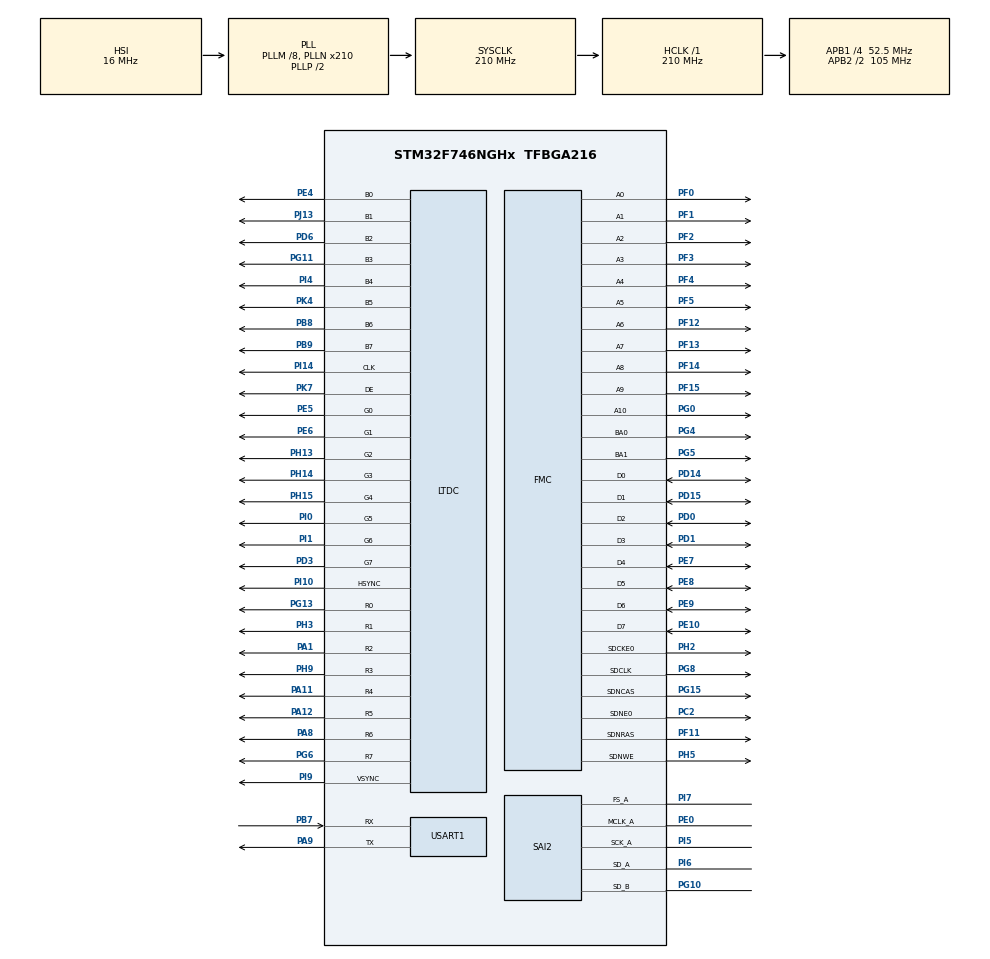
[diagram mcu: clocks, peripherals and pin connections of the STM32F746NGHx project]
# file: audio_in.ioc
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Dma.Request0=SAI2_B
Dma.SAI2_B.0.Direction=DMA_PERIPH_TO_MEMORY
Dma.SAI2_B.0.FIFOMode=DMA_FIFOMODE_DISABLE
Dma.SAI2_B.0.Instance=DMA2_Stream6
Dma.SAI2_B.0.MemDataAlignment=DMA_MDATAALIGN_WORD
Dma.SAI2_B.0.MemInc=DMA_MINC_ENABLE
Dma.SAI2_B.0.Mode=DMA_NORMAL
Dma.SAI2_B.0.PeriphDataAlignment=DMA_PDATAALIGN_WORD
Dma.SAI2_B.0.PeriphInc=DMA_PINC_DISABLE
Dma.SAI2_B.0.Priority=DMA_PRIORITY_LOW
Mcu.Family=STM32F7
Mcu.Name=STM32F746NGHx
Mcu.Package=TFBGA216
NVIC.DMA2_Stream6_IRQn=true\:0\:0\:false\:false\:true\:false\:true\:true
NVIC.PriorityGroup=NVIC_PRIORITYGROUP_4
NVIC.TIM1_UP_TIM10_IRQn=true\:15\:0\:false\:false\:true\:false\:true\:true
NVIC.TimeBase=TIM1_UP_TIM10_IRQn
NVIC.TimeBaseIP=TIM1
PA1.Mode=RGB888
PA1.Signal=LTDC_R2
PA11.Mode=RGB888
PA11.Signal=LTDC_R4
PA12.Mode=RGB888
PA12.Signal=LTDC_R5
PA8.Mode=RGB888
PA8.Signal=LTDC_R6
PA9.Mode=Asynchronous
PA9.Signal=USART1_TX
PB7.Mode=Asynchronous
PB7.Signal=USART1_RX
PB8.Mode=RGB888
PB8.Signal=LTDC_B6
PB9.Mode=RGB888
PB9.Signal=LTDC_B7
PC2.Mode=SdramChipSelect1_1
PC2.Signal=FMC_SDNE0
PD0.Signal=FMC_D2_DA2
PD1.Signal=FMC_D3_DA3
PD14.Signal=FMC_D0_DA0
PD15.Signal=FMC_D1_DA1
PD3.Mode=RGB888
PD3.Signal=LTDC_G7
PD6.Mode=RGB888
PD6.Signal=LTDC_B2
PE0.Mode=SAI_A_MasterWithClock
PE0.Signal=SAI2_MCLK_A
PE10.Signal=FMC_D7_DA7
PE4.Mode=RGB888
PE4.Signal=LTDC_B0
PE5.Mode=RGB888
PE5.Signal=LTDC_G0
PE6.Mode=RGB888
PE6.Signal=LTDC_G1
PE7.Signal=FMC_D4_DA4
PE8.Signal=FMC_D5_DA5
PE9.Signal=FMC_D6_DA6
PF0.Signal=FMC_A0
PF1.Signal=FMC_A1
PF11.Signal=FMC_SDNRAS
PF12.Signal=FMC_A6
PF13.Signal=FMC_A7
PF14.Signal=FMC_A8
PF15.Signal=FMC_A9
PF2.Signal=FMC_A2
PF3.Signal=FMC_A3
PF4.Signal=FMC_A4
PF5.Signal=FMC_A5
PG0.Signal=FMC_A10
PG10.Mode=SAI_B_SyncSlave
PG10.Signal=SAI2_SD_B
PG11.Mode=RGB888
PG11.Signal=LTDC_B3
PG13.Mode=RGB888
PG13.Signal=LTDC_R0
PG15.Signal=FMC_SDNCAS
PG4.Signal=FMC_A14_BA0
PG5.Signal=FMC_A15_BA1
PG6.Mode=RGB888
PG6.Signal=LTDC_R7
PG8.Signal=FMC_SDCLK
PH13.Mode=RGB888
PH13.Signal=LTDC_G2
PH14.Mode=RGB888
PH14.Signal=LTDC_G3
PH15.Mode=RGB888
PH15.Signal=LTDC_G4
PH2.Mode=SdramChipSelect1_1
PH2.Signal=FMC_SDCKE0
PH3.Mode=RGB888
PH3.Signal=LTDC_R1
PH5.Signal=FMC_SDNWE
PH9.Mode=RGB888
PH9.Signal=LTDC_R3
PI0.Mode=RGB888
PI0.Signal=LTDC_G5
PI1.Mode=RGB888
PI1.Signal=LTDC_G6
PI10.Mode=RGB888
PI10.Signal=LTDC_HSYNC
PI14.Mode=RGB888
PI14.Signal=LTDC_CLK
PI4.Mode=RGB888
PI4.Signal=LTDC_B4
PI5.Mode=SAI_A_MasterWithClock
PI5.Signal=SAI2_SCK_A
PI6.Mode=SAI_A_MasterWithClock
PI6.Signal=SAI2_SD_A
PI7.Mode=SAI_A_MasterWithClock
PI7.Signal=SAI2_FS_A
PI9.Mode=RGB888
PI9.Signal=LTDC_VSYNC
PJ13.Mode=RGB888
PJ13.Signal=LTDC_B1
PK4.Mode=RGB888
PK4.Signal=LTDC_B5
PK7.Mode=RGB888
PK7.Signal=LTDC_DE
ProjectManager.HeapSize=0x200
ProjectManager.StackSize=0x400
ProjectManager.TargetToolchain=STM32CubeIDE
RCC.AHBFreq_Value=210000000
RCC.APB1CLKDivider=RCC_HCLK_DIV4
RCC.APB1Freq_Value=52500000
RCC.APB1TimFreq_Value=105000000
RCC.APB2CLKDivider=RCC_HCLK_DIV2
RCC.APB2Freq_Value=105000000
RCC.APB2TimFreq_Value=210000000
RCC.CortexFreq_Value=210000000
RCC.HCLKFreq_Value=210000000
RCC.HSE_VALUE=25000000
RCC.HSI_VALUE=16000000
RCC.LSE_VALUE=32768
RCC.PLLM=8
RCC.PLLN=210
RCC.PLLSAIN=50
RCC.PLLSourceVirtual=RCC_PLLSOURCE_HSI
RCC.SYSCLKFreq_VALUE=210000000
RCC.SYSCLKSource=RCC_SYSCLKSOURCE_PLLCLK
RCC.USBFreq_Value=210000000
RCC.VCOOutputFreq_Value=420000000
SAI2.AudioFrequency-SAI_A_MasterWithClock=SAI_AUDIO_FREQUENCY_48K
SAI2.ErrorAudioFreq-SAI_A_MasterWithClock=1.72 %
SAI2.Instance-SAI_A_MasterWithClock=SAI$Index_Block_A
SAI2.Instance-SAI_B_SyncSlave=SAI$Index_Block_B
SAI2.MClockEnable-SAI_A_MasterWithClock=SAI_MASTERCLOCK_ENABLE
SAI2.RealAudioFreq-SAI_A_MasterWithClock=48.828 KHz
SAI2.VirtualMode-SAI_A_MasterWithClock=VM_MASTER
SAI2.VirtualMode-SAI_B_SyncSlave=VM_SLAVE
SH.FMC_A0.0=FMC_A0,11b-sda1
SH.FMC_A1.0=FMC_A1,11b-sda1
SH.FMC_A10.0=FMC_A10,11b-sda1
SH.FMC_A14_BA0.0=FMC_BA0,FourSdramBanks1
SH.FMC_A15_BA1.0=FMC_BA1,FourSdramBanks1
SH.FMC_A2.0=FMC_A2,11b-sda1
SH.FMC_A3.0=FMC_A3,11b-sda1
SH.FMC_A4.0=FMC_A4,11b-sda1
SH.FMC_A5.0=FMC_A5,11b-sda1
SH.FMC_A6.0=FMC_A6,11b-sda1
SH.FMC_A7.0=FMC_A7,11b-sda1
SH.FMC_A8.0=FMC_A8,11b-sda1
SH.FMC_A9.0=FMC_A9,11b-sda1
SH.FMC_D0_DA0.0=FMC_D0,sd-8b-d1
SH.FMC_D1_DA1.0=FMC_D1,sd-8b-d1
SH.FMC_D2_DA2.0=FMC_D2,sd-8b-d1
SH.FMC_D3_DA3.0=FMC_D3,sd-8b-d1
SH.FMC_D4_DA4.0=FMC_D4,sd-8b-d1
SH.FMC_D5_DA5.0=FMC_D5,sd-8b-d1
SH.FMC_D6_DA6.0=FMC_D6,sd-8b-d1
SH.FMC_D7_DA7.0=FMC_D7,sd-8b-d1
SH.FMC_SDCLK.0=FMC_SDCLK,11b-sda1
SH.FMC_SDNCAS.0=FMC_SDNCAS,11b-sda1
SH.FMC_SDNRAS.0=FMC_SDNRAS,11b-sda1
SH.FMC_SDNWE.0=FMC_SDNWE,11b-sda1
STMicroelectronics.X-CUBE-TOUCHGFX.4.23.0_IsPackSelfContextualization=true
USART1.VirtualMode-Asynchronous=VM_ASYNC
VP_DMA2D_VS_DMA2D.Mode=DMA2D_Activate
VP_SYS_VS_tim1.Mode=TIM1
board=STM32F746G-DISCO

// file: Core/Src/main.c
/* USER CODE BEGIN Header */
/**
  ******************************************************************************
  * @file           : main.c
  * @brief          : Main program body
  ******************************************************************************
  * @attention
  *
  * Copyright (c) 2024 STMicroelectronics.
  * All rights reserved.
  *
  * This software is licensed under terms that can be found in the LICENSE file
  * in the root directory of this software component.
  * If no LICENSE file comes with this software, it is provided AS-IS.
  *
  ******************************************************************************
  */
/* USER CODE END Header */
#include "main.h"

/* USER CODE BEGIN Includes */
#include "../Drivers/BSP/STM32746G-Discovery/stm32746g_discovery_audio.h"

/* USER CODE END Includes */

/* USER CODE BEGIN PD */
#define BUFF_SIZE 960
/* USER CODE END PD */

DMA2D_HandleTypeDef hdma2d;

LTDC_HandleTypeDef hltdc;

SAI_HandleTypeDef hsai_BlockA2;
SAI_HandleTypeDef hsai_BlockB2;
DMA_HandleTypeDef hdma_sai2_b;

UART_HandleTypeDef huart1;

SDRAM_HandleTypeDef hsdram1;

void SystemClock_Config(void);
void PeriphCommonClock_Config(void);
static void MX_GPIO_Init(void);
static void MX_DMA_Init(void);
static void MX_FMC_Init(void);
static void MX_USART1_UART_Init(void);
static void MX_DMA2D_Init(void);
static void MX_SAI2_Init(void);
static void MX_LTDC_Init(void);

int main(void)
{

  /* MCU Configuration--------------------------------------------------------*/

  /* Reset of all peripherals, Initializes the Flash interface and the Systick. */
  HAL_Init();

  /* Configure the system clock */
  SystemClock_Config();

/* Configure the peripherals common clocks */
  PeriphCommonClock_Config();

  /* Initialize all configured peripherals */
  MX_GPIO_Init();
  MX_DMA_Init();
  MX_FMC_Init();
  MX_USART1_UART_Init();
  MX_DMA2D_Init();
  MX_SAI2_Init();
  MX_LTDC_Init();
  /* USER CODE BEGIN 2 */
  BSP_AUDIO_IN_OUT_Init(INPUT_DEVICE_DIGITAL_MICROPHONE_2, OUTPUT_DEVICE_AUTO, AUDIO_FREQUENCY_48K, 0 ,0);
  uint16_t buf[BUFF_SIZE];
  BSP_AUDIO_IN_Record(buf, BUFF_SIZE);
  //BSP_AUDIO_OUT_Play(buf, BUFF_SIZE*2);
  /* USER CODE END 2 */

  /* Infinite loop */
  while (1)
  {

  }
}

void SystemClock_Config(void)
{
  RCC_OscInitTypeDef RCC_OscInitStruct = {0};
  RCC_ClkInitTypeDef RCC_ClkInitStruct = {0};

  /** Configure the main internal regulator output voltage
  */
  __HAL_RCC_PWR_CLK_ENABLE();
  __HAL_PWR_VOLTAGESCALING_CONFIG(PWR_REGULATOR_VOLTAGE_SCALE1);

  /** Initializes the RCC Oscillators according to the specified parameters
  * in the RCC_OscInitTypeDef structure.
  */
  RCC_OscInitStruct.OscillatorType = RCC_OSCILLATORTYPE_HSI;
  RCC_OscInitStruct.HSIState = RCC_HSI_ON;
  RCC_OscInitStruct.HSICalibrationValue = RCC_HSICALIBRATION_DEFAULT;
  RCC_OscInitStruct.PLL.PLLState = RCC_PLL_ON;
  RCC_OscInitStruct.PLL.PLLSource = RCC_PLLSOURCE_HSI;
  RCC_OscInitStruct.PLL.PLLM = 8;
  RCC_OscInitStruct.PLL.PLLN = 210;
  RCC_OscInitStruct.PLL.PLLP = RCC_PLLP_DIV2;
  RCC_OscInitStruct.PLL.PLLQ = 2;
  if (HAL_RCC_OscConfig(&RCC_OscInitStruct) != HAL_OK)
  {
    Error_Handler();
  }

  /** Activate the Over-Drive mode
  */
  if (HAL_PWREx_EnableOverDrive() != HAL_OK)
  {
    Error_Handler();
  }

  /** Initializes the CPU, AHB and APB buses clocks
  */
  RCC_ClkInitStruct.ClockType = RCC_CLOCKTYPE_HCLK|RCC_CLOCKTYPE_SYSCLK
                              |RCC_CLOCKTYPE_PCLK1|RCC_CLOCKTYPE_PCLK2;
  RCC_ClkInitStruct.SYSCLKSource = RCC_SYSCLKSOURCE_PLLCLK;
  RCC_ClkInitStruct.AHBCLKDivider = RCC_SYSCLK_DIV1;
  RCC_ClkInitStruct.APB1CLKDivider = RCC_HCLK_DIV4;
  RCC_ClkInitStruct.APB2CLKDivider = RCC_HCLK_DIV2;

  if (HAL_RCC_ClockConfig(&RCC_ClkInitStruct, FLASH_LATENCY_6) != HAL_OK)
  {
    Error_Handler();
  }
}

void PeriphCommonClock_Config(void)
{
  RCC_PeriphCLKInitTypeDef PeriphClkInitStruct = {0};

  /** Initializes the peripherals clock
  */
  PeriphClkInitStruct.PeriphClockSelection = RCC_PERIPHCLK_LTDC|RCC_PERIPHCLK_SAI2;
  PeriphClkInitStruct.PLLSAI.PLLSAIN = 50;
  PeriphClkInitStruct.PLLSAI.PLLSAIR = 2;
  PeriphClkInitStruct.PLLSAI.PLLSAIQ = 2;
  PeriphClkInitStruct.PLLSAI.PLLSAIP = RCC_PLLSAIP_DIV2;
  PeriphClkInitStruct.PLLSAIDivQ = 1;
  PeriphClkInitStruct.PLLSAIDivR = RCC_PLLSAIDIVR_2;
  PeriphClkInitStruct.Sai2ClockSelection = RCC_SAI2CLKSOURCE_PLLSAI;
  if (HAL_RCCEx_PeriphCLKConfig(&PeriphClkInitStruct) != HAL_OK)
  {
    Error_Handler();
  }
}

static void MX_DMA2D_Init(void)
{

  hdma2d.Instance = DMA2D;
  hdma2d.Init.Mode = DMA2D_M2M;
  hdma2d.Init.ColorMode = DMA2D_OUTPUT_ARGB8888;
  hdma2d.Init.OutputOffset = 0;
  hdma2d.LayerCfg[1].InputOffset = 0;
  hdma2d.LayerCfg[1].InputColorMode = DMA2D_INPUT_ARGB8888;
  hdma2d.LayerCfg[1].AlphaMode = DMA2D_NO_MODIF_ALPHA;
  hdma2d.LayerCfg[1].InputAlpha = 0;
  if (HAL_DMA2D_Init(&hdma2d) != HAL_OK)
  {
    Error_Handler();
  }
  if (HAL_DMA2D_ConfigLayer(&hdma2d, 1) != HAL_OK)
  {
    Error_Handler();
  }

}

static void MX_LTDC_Init(void)
{

  LTDC_LayerCfgTypeDef pLayerCfg = {0};
  LTDC_LayerCfgTypeDef pLayerCfg1 = {0};

  hltdc.Instance = LTDC;
  hltdc.Init.HSPolarity = LTDC_HSPOLARITY_AL;
  hltdc.Init.VSPolarity = LTDC_VSPOLARITY_AL;
  hltdc.Init.DEPolarity = LTDC_DEPOLARITY_AL;
  hltdc.Init.PCPolarity = LTDC_PCPOLARITY_IPC;
  hltdc.Init.HorizontalSync = 7;
  hltdc.Init.VerticalSync = 3;
  hltdc.Init.AccumulatedHBP = 14;
  hltdc.Init.AccumulatedVBP = 5;
  hltdc.Init.AccumulatedActiveW = 654;
  hltdc.Init.AccumulatedActiveH = 485;
  hltdc.Init.TotalWidth = 660;
  hltdc.Init.TotalHeigh = 487;
  hltdc.Init.Backcolor.Blue = 0;
  hltdc.Init.Backcolor.Green = 0;
  hltdc.Init.Backcolor.Red = 0;
  if (HAL_LTDC_Init(&hltdc) != HAL_OK)
  {
    Error_Handler();
  }
  pLayerCfg.WindowX0 = 0;
  pLayerCfg.WindowX1 = 0;
  pLayerCfg.WindowY0 = 0;
  pLayerCfg.WindowY1 = 0;
  pLayerCfg.PixelFormat = LTDC_PIXEL_FORMAT_ARGB8888;
  pLayerCfg.Alpha = 0;
  pLayerCfg.Alpha0 = 0;
  pLayerCfg.BlendingFactor1 = LTDC_BLENDING_FACTOR1_CA;
  pLayerCfg.BlendingFactor2 = LTDC_BLENDING_FACTOR2_CA;
  pLayerCfg.FBStartAdress = 0;
  pLayerCfg.ImageWidth = 0;
  pLayerCfg.ImageHeight = 0;
  pLayerCfg.Backcolor.Blue = 0;
  pLayerCfg.Backcolor.Green = 0;
  pLayerCfg.Backcolor.Red = 0;
  if (HAL_LTDC_ConfigLayer(&hltdc, &pLayerCfg, 0) != HAL_OK)
  {
    Error_Handler();
  }
  pLayerCfg1.WindowX0 = 0;
  pLayerCfg1.WindowX1 = 0;
  pLayerCfg1.WindowY0 = 0;
  pLayerCfg1.WindowY1 = 0;
  pLayerCfg1.PixelFormat = LTDC_PIXEL_FORMAT_ARGB8888;
  pLayerCfg1.Alpha = 0;
  pLayerCfg1.Alpha0 = 0;
  pLayerCfg1.BlendingFactor1 = LTDC_BLENDING_FACTOR1_CA;
  pLayerCfg1.BlendingFactor2 = LTDC_BLENDING_FACTOR2_CA;
  pLayerCfg1.FBStartAdress = 0;
  pLayerCfg1.ImageWidth = 0;
  pLayerCfg1.ImageHeight = 0;
  pLayerCfg1.Backcolor.Blue = 0;
  pLayerCfg1.Backcolor.Green = 0;
  pLayerCfg1.Backcolor.Red = 0;
  if (HAL_LTDC_ConfigLayer(&hltdc, &pLayerCfg1, 1) != HAL_OK)
  {
    Error_Handler();
  }

}

static void MX_SAI2_Init(void)
{

  hsai_BlockA2.Instance = SAI2_Block_A;
  hsai_BlockA2.Init.Protocol = SAI_FREE_PROTOCOL;
  hsai_BlockA2.Init.AudioMode = SAI_MODEMASTER_TX;
  hsai_BlockA2.Init.DataSize = SAI_DATASIZE_8;
  hsai_BlockA2.Init.FirstBit = SAI_FIRSTBIT_MSB;
  hsai_BlockA2.Init.ClockStrobing = SAI_CLOCKSTROBING_FALLINGEDGE;
  hsai_BlockA2.Init.Synchro = SAI_ASYNCHRONOUS;
  hsai_BlockA2.Init.OutputDrive = SAI_OUTPUTDRIVE_DISABLE;
  hsai_BlockA2.Init.NoDivider = SAI_MASTERDIVIDER_ENABLE;
  hsai_BlockA2.Init.FIFOThreshold = SAI_FIFOTHRESHOLD_EMPTY;
  hsai_BlockA2.Init.AudioFrequency = SAI_AUDIO_FREQUENCY_48K;
  hsai_BlockA2.Init.SynchroExt = SAI_SYNCEXT_DISABLE;
  hsai_BlockA2.Init.MonoStereoMode = SAI_STEREOMODE;
  hsai_BlockA2.Init.CompandingMode = SAI_NOCOMPANDING;
  hsai_BlockA2.Init.TriState = SAI_OUTPUT_NOTRELEASED;
  hsai_BlockA2.FrameInit.FrameLength = 8;
  hsai_BlockA2.FrameInit.ActiveFrameLength = 1;
  hsai_BlockA2.FrameInit.FSDefinition = SAI_FS_STARTFRAME;
  hsai_BlockA2.FrameInit.FSPolarity = SAI_FS_ACTIVE_LOW;
  hsai_BlockA2.FrameInit.FSOffset = SAI_FS_FIRSTBIT;
  hsai_BlockA2.SlotInit.FirstBitOffset = 0;
  hsai_BlockA2.SlotInit.SlotSize = SAI_SLOTSIZE_DATASIZE;
  hsai_BlockA2.SlotInit.SlotNumber = 1;
  hsai_BlockA2.SlotInit.SlotActive = 0x00000000;
  if (HAL_SAI_Init(&hsai_BlockA2) != HAL_OK)
  {
    Error_Handler();
  }
  hsai_BlockB2.Instance = SAI2_Block_B;
  hsai_BlockB2.Init.Protocol = SAI_FREE_PROTOCOL;
  hsai_BlockB2.Init.AudioMode = SAI_MODESLAVE_RX;
  hsai_BlockB2.Init.DataSize = SAI_DATASIZE_8;
  hsai_BlockB2.Init.FirstBit = SAI_FIRSTBIT_MSB;
  hsai_BlockB2.Init.ClockStrobing = SAI_CLOCKSTROBING_FALLINGEDGE;
  hsai_BlockB2.Init.Synchro = SAI_SYNCHRONOUS;
  hsai_BlockB2.Init.OutputDrive = SAI_OUTPUTDRIVE_DISABLE;
  hsai_BlockB2.Init.FIFOThreshold = SAI_FIFOTHRESHOLD_EMPTY;
  hsai_BlockB2.Init.SynchroExt = SAI_SYNCEXT_DISABLE;
  hsai_BlockB2.Init.MonoStereoMode = SAI_STEREOMODE;
  hsai_BlockB2.Init.CompandingMode = SAI_NOCOMPANDING;
  hsai_BlockB2.Init.TriState = SAI_OUTPUT_NOTRELEASED;
  hsai_BlockB2.FrameInit.FrameLength = 8;
  hsai_BlockB2.FrameInit.ActiveFrameLength = 1;
  hsai_BlockB2.FrameInit.FSDefinition = SAI_FS_STARTFRAME;
  hsai_BlockB2.FrameInit.FSPolarity = SAI_FS_ACTIVE_LOW;
  hsai_BlockB2.FrameInit.FSOffset = SAI_FS_FIRSTBIT;
  hsai_BlockB2.SlotInit.FirstBitOffset = 0;
  hsai_BlockB2.SlotInit.SlotSize = SAI_SLOTSIZE_DATASIZE;
  hsai_BlockB2.SlotInit.SlotNumber = 1;
  hsai_BlockB2.SlotInit.SlotActive = 0x00000000;
  if (HAL_SAI_Init(&hsai_BlockB2) != HAL_OK)
  {
    Error_Handler();
  }

}

static void MX_USART1_UART_Init(void)
{

  huart1.Instance = USART1;
  huart1.Init.BaudRate = 115200;
  huart1.Init.WordLength = UART_WORDLENGTH_8B;
  huart1.Init.StopBits = UART_STOPBITS_1;
  huart1.Init.Parity = UART_PARITY_NONE;
  huart1.Init.Mode = UART_MODE_TX_RX;
  huart1.Init.HwFlowCtl = UART_HWCONTROL_NONE;
  huart1.Init.OverSampling = UART_OVERSAMPLING_16;
  huart1.Init.OneBitSampling = UART_ONE_BIT_SAMPLE_DISABLE;
  huart1.AdvancedInit.AdvFeatureInit = UART_ADVFEATURE_NO_INIT;
  if (HAL_UART_Init(&huart1) != HAL_OK)
  {
    Error_Handler();
  }

}

static void MX_DMA_Init(void)
{

  /* DMA controller clock enable */
  __HAL_RCC_DMA2_CLK_ENABLE();

  /* DMA interrupt init */
  /* DMA2_Stream6_IRQn interrupt configuration */
  HAL_NVIC_SetPriority(DMA2_Stream6_IRQn, 0, 0);
  HAL_NVIC_EnableIRQ(DMA2_Stream6_IRQn);

}

/* FMC initialization function */
static void MX_FMC_Init(void)
{

  FMC_SDRAM_TimingTypeDef SdramTiming = {0};

  /** Perform the SDRAM1 memory initialization sequence
  */
  hsdram1.Instance = FMC_SDRAM_DEVICE;
  /* hsdram1.Init */
  hsdram1.Init.SDBank = FMC_SDRAM_BANK1;
  hsdram1.Init.ColumnBitsNumber = FMC_SDRAM_COLUMN_BITS_NUM_8;
  hsdram1.Init.RowBitsNumber = FMC_SDRAM_ROW_BITS_NUM_11;
  hsdram1.Init.MemoryDataWidth = FMC_SDRAM_MEM_BUS_WIDTH_8;
  hsdram1.Init.InternalBankNumber = FMC_SDRAM_INTERN_BANKS_NUM_4;
  hsdram1.Init.CASLatency = FMC_SDRAM_CAS_LATENCY_1;
  hsdram1.Init.WriteProtection = FMC_SDRAM_WRITE_PROTECTION_DISABLE;
  hsdram1.Init.SDClockPeriod = FMC_SDRAM_CLOCK_DISABLE;
  hsdram1.Init.ReadBurst = FMC_SDRAM_RBURST_DISABLE;
  hsdram1.Init.ReadPipeDelay = FMC_SDRAM_RPIPE_DELAY_0;
  /* SdramTiming */
  SdramTiming.LoadToActiveDelay = 16;
  SdramTiming.ExitSelfRefreshDelay = 16;
  SdramTiming.SelfRefreshTime = 16;
  SdramTiming.RowCycleDelay = 16;
  SdramTiming.WriteRecoveryTime = 16;
  SdramTiming.RPDelay = 16;
  SdramTiming.RCDDelay = 16;

  if (HAL_SDRAM_Init(&hsdram1, &SdramTiming) != HAL_OK)
  {
    Error_Handler( );
  }

}

static void MX_GPIO_Init(void)
{

  /* GPIO Ports Clock Enable */
  __HAL_RCC_GPIOE_CLK_ENABLE();
  __HAL_RCC_GPIOB_CLK_ENABLE();
  __HAL_RCC_GPIOG_CLK_ENABLE();
  __HAL_RCC_GPIOJ_CLK_ENABLE();
  __HAL_RCC_GPIOD_CLK_ENABLE();
  __HAL_RCC_GPIOA_CLK_ENABLE();
  __HAL_RCC_GPIOI_CLK_ENABLE();
  __HAL_RCC_GPIOK_CLK_ENABLE();
  __HAL_RCC_GPIOF_CLK_ENABLE();
  __HAL_RCC_GPIOH_CLK_ENABLE();
  __HAL_RCC_GPIOC_CLK_ENABLE();

}

void HAL_TIM_PeriodElapsedCallback(TIM_HandleTypeDef *htim)
{
  if (htim->Instance == TIM1) {
    HAL_IncTick();
  }
}

void Error_Handler(void)
{
  __disable_irq();
  while (1)
  {
  }
}
